# SMS_SEC_MGR_0_SMS_TIFS_SECMGR_44234000h register map
Vendor: Texas Instruments
Peripheral module from a debugger description file (folder AM275x).
Registers are 32-bit, read-write, reset 0x0 unless marked. A register's access mark holds for its fields unless they carry their own. Offsets are as the file gives them; lines under a group give offsets from that group; [hi:lo] are bit positions; {n}, {i} and the like mark numbered series; 'fields as' and 'values as' point back to an identical list; <NAME> marks a mode.

## SMS_TIFS_SECMGR
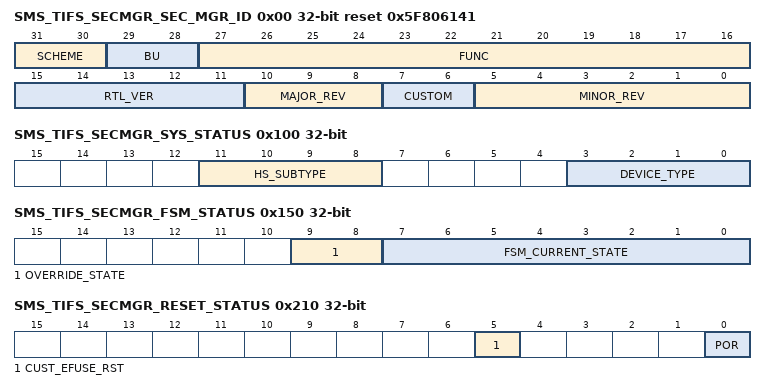
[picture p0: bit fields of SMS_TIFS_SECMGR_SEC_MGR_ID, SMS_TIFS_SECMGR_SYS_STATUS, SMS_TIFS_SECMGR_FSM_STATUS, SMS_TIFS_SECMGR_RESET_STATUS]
0x00 SMS_TIFS_SECMGR_SEC_MGR_ID ro reset 0x5F806141 — This is the standard TI peripheral ID register that exists at address 0 in the peripheral space
  [31:30] SCHEME — Used to distinguish which ID numbering scheme is used. Reset Source: sms_custom_rst_mod_g_rst_n
  [29:28] BU — BU identifier Reset Source: sms_custom_rst_mod_g_rst_n
  [27:16] FUNC — Module family. Reset Source: sms_custom_rst_mod_g_rst_n
  [15:11] RTL_VER — RTL version. R of X.Y.R.Z Reset Source: sms_custom_rst_mod_g_rst_n
  [10:8] MAJOR_REV — Major revision. X of X.Y.R.Z Reset Source: sms_custom_rst_mod_g_rst_n
  [7:6] CUSTOM — Special version number Reset Source: sms_custom_rst_mod_g_rst_n
  [5:0] MINOR_REV — Minor revision. Y of X.Y.R.Z Reset Source: sms_custom_rst_mod_g_rst_n
0x100 SMS_TIFS_SECMGR_SYS_STATUS ro — The System Status Register contains status information on the state of the security system. This is the only register that must be read to determine the status of the entire system. It is a readonly register and some bit will be replicated in other registers. This register is reset on POR only.
  [11:8] HS_SUBTYPE — HS/EMU Sub-type. 0xA = Field Securable. Else = Security Enforced 10 Field SecurableElse Security Enforced
  [3:0] DEVICE_TYPE — Decoded device type 4'b00 GENERAL_PURPOSE114'b01 TEST014'b10 EMULATOR014'b10 HIGH_SECURITY10Other BAD
0x150 SMS_TIFS_SECMGR_FSM_STATUS ro — The FSM Status Register contains Secure FSM state machine information
  [9:8] OVERRIDE_STATE — This is the override status 2'b00 No override2'b01 Override without SMS2'b10 Reserved2'b11 Override with SMS
  [7:0] FSM_CURRENT_STATE — This is the state machine FSM current state variable Reset Source: sms_custom_rst_mod_g_rst_n
0x210 SMS_TIFS_SECMGR_RESET_STATUS ro — The Reset Status Register provides visibility of resets within the system. These bits are read-only and will be cleared when a 1 is written to a given bit location. They will record the fact that a given reset occurred.
  [5] CUST_EFUSE_RST — Captures reset events on port: sec_efc_fclrz Reset Source: sms_custom_rst_mod_g_rst_n
  [0] POR — Captures reset events on port: por_rst_n Reset Source: sms_custom_rst_mod_g_rst_n
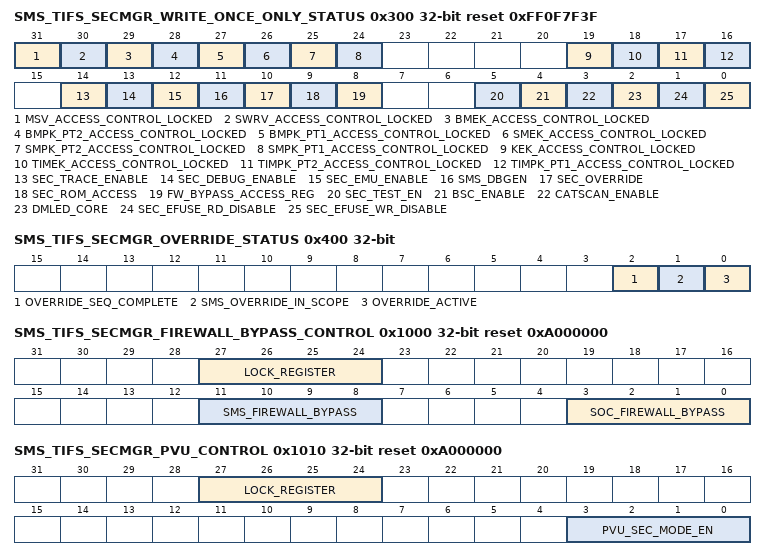
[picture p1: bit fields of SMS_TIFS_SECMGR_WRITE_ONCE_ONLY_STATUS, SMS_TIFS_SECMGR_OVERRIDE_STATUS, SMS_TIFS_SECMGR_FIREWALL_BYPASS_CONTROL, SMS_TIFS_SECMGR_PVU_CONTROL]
0x300 SMS_TIFS_SECMGR_WRITE_ONCE_ONLY_STATUS ro reset 0xFF0F7F3F — As a debug aid we need to be able to read the write-once only bits to know their state. This register makes all these write-once only flags visible in current state.
  [31] MSV_ACCESS_CONTROL_LOCKED — 0 MSV access control register locked1 MSV access control register not locked
  [30] SWRV_ACCESS_CONTROL_LOCKED — 0 SWRV access control register locked1 SWRV access control register not locked
  [29] BMEK_ACCESS_CONTROL_LOCKED — 0 BMEK access control register locked1 BMEK access control register not locked
  [28] BMPK_PT2_ACCESS_CONTROL_LOCKED — 0 BMPK-Part2 access control register locked1 BMPK-Part2 access control register not locked
  [27] BMPK_PT1_ACCESS_CONTROL_LOCKED — 0 BMPK-Part1 access control register locked1 BMPK-Part1 access control register not locked
  [26] SMEK_ACCESS_CONTROL_LOCKED — 0 SMEK access control register locked1 SMEK access control register not locked
  [25] SMPK_PT2_ACCESS_CONTROL_LOCKED — 0 SMPK-Part2 access control register locked1 SMPK-Part2 access control register not locked
  [24] SMPK_PT1_ACCESS_CONTROL_LOCKED — 0 SMPK-Part1 access control register locked1 SMPK-Part1 access control register not locked
  [19] KEK_ACCESS_CONTROL_LOCKED — 0 KEK access control register locked1 KEK access control register not locked
  [18] TIMEK_ACCESS_CONTROL_LOCKED — 0 TI MEK access control register locked1 TI MEK access control register not locked
  [17] TIMPK_PT2_ACCESS_CONTROL_LOCKED — 0 TI MPK-Part2 access control register locked1 TI MPK-Part2 access control register not locked
  [16] TIMPK_PT1_ACCESS_CONTROL_LOCKED — 0 TI MPK-Part1 access control register locked1 TI MPK-Part1 access control register not locked
  [14] SEC_TRACE_ENABLE — 0 Secure Trace Enable access control register locked1 Secure Trace Enable access control register not locked
  [13] SEC_DEBUG_ENABLE — 0 Secure Debug Enable access control register locked1 Secure Debug Enable access control register not locked
  [12] SEC_EMU_ENABLE — 0 Secure Emulation Enable access control register locked1 Secure Emulation Enable access control register not locked
  [11] SMS_DBGEN — 0 SMS Debug Enable access control register locked1 SMS Debug Enable access control register not locked
  [10] SEC_OVERRIDE — 0 Security Override access control register locked1 Security Override access control register not locked
  [9] SEC_ROM_ACCESS — 0 Secure ROM access control register locked1 Secure ROM access control register not locked
  [8] FW_BYPASS_ACCESS_REG — 0 Firewall Bypass access control register locked1 Firewall Bypass access control register not locked
  [5] SEC_TEST_EN — 0 Secure Test Enable access control register locked1 Secure Test Enable access control register not locked
  [4] BSC_ENABLE — 0 Boundary Scan Enable access control register locked1 Boundary Scan Enable access control register not locked
  [3] CATSCAN_ENABLE — 0 Catscan Enable access control register locked1 Catscan Enable access control register not locked
  [2] DMLED_CORE — 0 DMLED Core control register locked1 DMLED Core control register not locked
  [1] SEC_EFUSE_RD_DISABLE — 0 Security EFUSE Read Disable register locked1 Security EFUSE Read Disable register not locked
  [0] SEC_EFUSE_WR_DISABLE — 0 Security EFUSE Write Disable register locked1 Security EFUSE Write Disable register not locked
0x400 SMS_TIFS_SECMGR_OVERRIDE_STATUS ro — This Register reflects the status of Override request.
  [2] OVERRIDE_SEQ_COMPLETE — 1 HW Override sequence finished
  [1] SMS_OVERRIDE_IN_SCOPE — 0 SMS Override not active1 SMS Override active
  [0] OVERRIDE_ACTIVE — 0 Override not active0 Override active
0x700 SMS_TIFS_SECMGR_TI_MPK_PART1_STATUS_REG_j ro — This register echoes the TI MPK-Part1 value, the MPK value can be muted via MPK Access control register.
  [31:0] TI_MPK — TI MP value as read from TI MPK Data Reg. This register is mere echo of Data Register Reset Source: sms_custom_rst_mod_g_rst_n
0x750 SMS_TIFS_SECMGR_TI_MPK_PART2_STATUS_REG_j ro — This register echoes the TI MPK-Part2 value, the MPK value can be muted via MPK Access control register.
  fields as SMS_TIFS_SECMGR_TI_MPK_PART1_STATUS_REG_j
0x780 SMS_TIFS_SECMGR_TI_MEK_ID_STATUS_REG ro — This register echoes the TI MEK ID value, this is used to ID the key used for MEK.
  [31:0] TI_MEK_ID — TI MEK ID value as read from TI MEK ID data register, this is mere echo of TI MEK ID Register. Reset Source: sms_custom_rst_mod_g_rst_n
0x800 SMS_TIFS_SECMGR_SMPK_PART1_STATUS_REG_j ro — This register echoes the SMPK-Part1 value, the MPK value can be muted via MPK Access control register.
  [31:0] SMPK — SMPK value as read from SMPK Data Register. This register is mere echo of SMPK Data register. Reset Source: sms_custom_rst_mod_g_rst_n
0x850 SMS_TIFS_SECMGR_SMPK_PART2_STATUS_REG_j ro — This register echoes the SMPK-Part2 value, the MPK value can be muted via MPK Access control register.
  fields as SMS_TIFS_SECMGR_SMPK_PART1_STATUS_REG_j
0x880 SMS_TIFS_SECMGR_SMEK_ID_STATUS_REG ro — This register echoes the SMEK ID value, this is used to ID the key used for SMEK.
  [31:0] SMEK — SMEK ID value as read from SMEK ID data register, this is mere echo of SMEK ID Register. Reset Source: sms_custom_rst_mod_g_rst_n
0x900 SMS_TIFS_SECMGR_BMPK_PART1_STATUS_REG_j ro — This register echoes the BMPK-Part1 value, the MPK value can be muted via MPK Access control register.
  [31:0] BMPK — BMPK value as read from BMPK Data Register. This register is mere echo of BMPK Data register. Reset Source: sms_custom_rst_mod_g_rst_n
0x950 SMS_TIFS_SECMGR_BMPK_PART2_STATUS_REG_j ro — This register echoes the BMPK-Part2 value, the MPK value can be muted via MPK Access control register.
  fields as SMS_TIFS_SECMGR_BMPK_PART1_STATUS_REG_j
0x980 SMS_TIFS_SECMGR_BMEK_ID_STATUS_REG ro — This register echoes the BMEK ID value, this is used to ID the key used for BMEK.
  [31:0] BMEK — BMEK ID value as read from BMEK ID data register, this is mere echo of BMEK ID Register. Reset Source: sms_custom_rst_mod_g_rst_n
0xD00 SMS_TIFS_SECMGR_SWRV_STATUS_REG_j ro — This register echoes the SWRV value, the SWRV value can be muted via SWRV Access control register.
  [31:0] SWRV — SWRV value as read from SWRV Data Register. This register is mere echo of SWRV Data register. Reset Source: sms_custom_rst_mod_g_rst_n
0xD50 SMS_TIFS_SECMGR_MSV_STATUS_REG ro — This register echoes the MSV value, the MSV value can be muted via MSV Access control register.
  [23:0] MSV — MSV value as read from MSV Data Register. This register is mere echo of MSV Data register. Reset Source: sms_custom_rst_mod_g_rst_n
0x1000 SMS_TIFS_SECMGR_FIREWALL_BYPASS_CONTROL reset 0xA000000 — This register controls the bypass feature for all SoC firewall. Once locked, the register cannot be changed till POR.
  [27:24] LOCK_REGISTER — Unlock code is 0xA, if value is anything else the register locks, once locked this register cannot be changed till POR. Rest Register is locked10 Register is unlocked
  [11:8] SMS_FIREWALL_BYPASS — Writing code 0xA will put SMS firewall in bypass mode. Please refer to firewall spec for bypass mode operation. 0 Not in bypass mode10 Bypass
  [3:0] SOC_FIREWALL_BYPASS — Writing code 0xA will put all SoC firewall in bypass mode, excluding SMS. Please refer to firewall spec for bypass mode operation 0 Not in bypass mode10 Bypass
0x1010 SMS_TIFS_SECMGR_PVU_CONTROL reset 0xA000000 — This register controls the security of PVU/IO-MMU module. Once locked, the register cannot be changed till POR.
  [27:24] LOCK_REGISTER — Unlock code is 0xA, if value is anything else the register locks, once locked this register cannot be changed till POR. Reset Source: sms_custom_rst_mod_g_rst_n
  [3:0] PVU_SEC_MODE_EN — Writing code 0xA allows PVC to operate in secure mode. Reset Source: sms_custom_rst_mod_g_rst_n
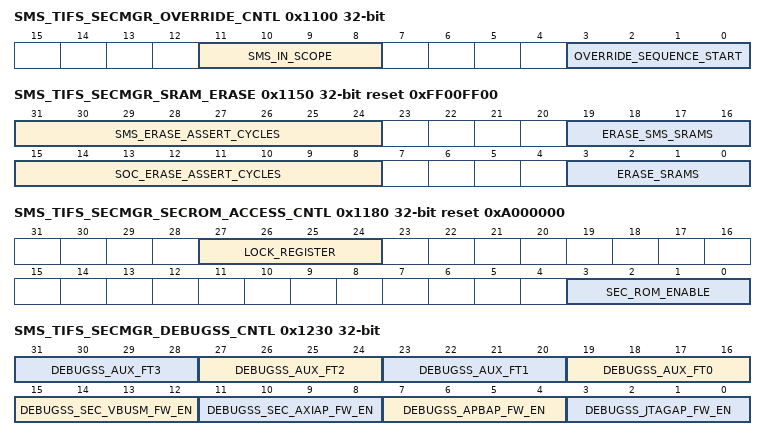
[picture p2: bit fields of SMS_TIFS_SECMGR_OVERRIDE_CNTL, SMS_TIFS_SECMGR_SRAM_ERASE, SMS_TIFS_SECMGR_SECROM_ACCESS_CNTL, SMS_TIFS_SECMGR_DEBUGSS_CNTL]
0x1100 SMS_TIFS_SECMGR_OVERRIDE_CNTL — Override sequence start register, writing 0xA start the override sequence as documented. This register can only be written once during each POR and the value is sticky.
  [11:8] SMS_IN_SCOPE — Writing code 0xA will put SMS also in in scope of override, please refer to flow in previous section. This must be set along with override_sequence_start. Reset Source: sms_custom_rst_mod_g_rst_n
  [3:0] OVERRIDE_SEQUENCE_START — Override sequence start bit, Writing 0xA starts the operation Reset Source: sms_custom_rst_mod_g_rst_n
0x1104 SMS_TIFS_SECMGR_OVERRIDE_DELAY_LOOP reset 0xFFFF — This register holds delay loop counter to allow SMS to enter WFI before SMS override is effeictive.
  [31:0] SMS_OVERRIDE_DELAY_LOOP_CNT — SMS Delay loop counter, override is effective when counter reaches Zero. This counter is running on PLL output clock , hence ROM/SW must ensure delay based on system PLL SMS clock. Reset Source: sms_custom_rst_mod_g_rst_n
0x1150 SMS_TIFS_SECMGR_SRAM_ERASE reset 0xFF00FF00 — This register control the Erase function of SRAM and ROM access control.
  [31:24] SMS_ERASE_ASSERT_CYCLES — This MMR control the assertion time of SMS Erase signal. This is required as certain SRAM erase logic may have time requirement to keep signal asserted. Runs as same clock as Sec-mgr clock. Reset Source: sms_custom_rst_mod_g_rst_n
  [19:16] ERASE_SMS_SRAMS — Writing code 0xA will send signal to erase SMS SRAM, this will erase all SMS SRAM including data and code SRAM. Care must be taken to ensure SMS Cortex-M4F is in not executing from SRAM when this signal is asserted. Reset Source: sms_custom_rst_mod_g_rst_n
  [15:8] SOC_ERASE_ASSERT_CYCLES — This MMR control the assertion time of SOC Erase signal. This is required as certain SRAM erase logic may have time requirement to keep signal asserted. Runs as same clock as Sec-mgr clock. Reset Source: sms_custom_rst_mod_g_rst_n
  [3:0] ERASE_SRAMS — Writing code 0xA will send signal to all SoC level SRAM to erase the RAM. This bit does not erase SMS internal SRAM. Reset Source: sms_custom_rst_mod_g_rst_n
0x1180 SMS_TIFS_SECMGR_SECROM_ACCESS_CNTL reset 0xA000000 — This register controls the Erase function of SRAM and ROM access control.
  [27:24] LOCK_REGISTER — Unlock code is 0xA, if value is anything else the register locks, once locked this register cannot be changed till POR Reset Source: sms_custom_rst_mod_g_rst_n
  [3:0] SEC_ROM_ENABLE — Writing code 0xA will enable access to secure ROM, for all other value the secure ROM is disabled. Reset Source: sms_custom_rst_mod_g_rst_n
0x1220 SMS_TIFS_SECMGR_DEBUGSS_DOM reset 0x3CE — This register controls the DebugSS DOM
  [10:0] DEBUGSS_SEC_CTL_DOM — DOM value as per DebugSS spec Reset Source: sms_custom_rst_mod_g_rst_n
0x1230 SMS_TIFS_SECMGR_DEBUGSS_CNTL — This register controls DebugSS Internal Firewall. This register can be locked. Once locked, the register cannot be changed until POR
  [4n+19:4n+16] DEBUGSS_AUX_FT{n} (n=0..3) — Writing code 0xA will assert signal debugss_aux_ft_signals bit {n} Reset Source: sms_custom_rst_mod_g_rst_n
  [15:12] DEBUGSS_SEC_VBUSM_FW_EN — Writing code 0xA will enable DebugSS internal VBUSM firewall interface, else it is disabled Reset Source: sms_custom_rst_mod_g_rst_n
  [11:8] DEBUGSS_SEC_AXIAP_FW_EN — Writing code 0xA will enable DebugSS internal AXI AP firewall interface, else it is disabled Reset Source: sms_custom_rst_mod_g_rst_n
  [7:4] DEBUGSS_APBAP_FW_EN — Writing code 0xA will enable DebugSS internal APB AP firewall interface, else it is disabled Reset Source: sms_custom_rst_mod_g_rst_n
  [3:0] DEBUGSS_JTAGAP_FW_EN — Writing code 0xA will enable DebugSS internal JTAG firewall interface, else it is disabled Reset Source: sms_custom_rst_mod_g_rst_n
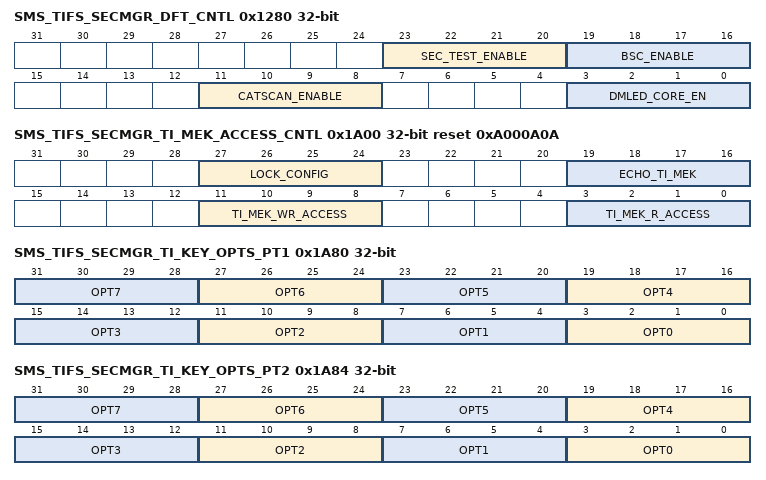
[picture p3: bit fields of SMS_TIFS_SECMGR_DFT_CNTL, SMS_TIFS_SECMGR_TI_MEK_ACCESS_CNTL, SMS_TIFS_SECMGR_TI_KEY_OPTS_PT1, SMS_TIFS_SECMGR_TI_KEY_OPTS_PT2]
0x1280 SMS_TIFS_SECMGR_DFT_CNTL — This register controls the DFT access of the device. These bits can only be written once during each POR.
  [23:20] SEC_TEST_ENABLE — Control the use of Test Enable. Writing a 0xA will enable test Reset Source: sms_custom_rst_mod_g_rst_n
  [19:16] BSC_ENABLE — Control the use of Boundary Scan Chain. Writing a 0xA will enable BSCAN Reset Source: sms_custom_rst_mod_g_rst_n
  [11:8] CATSCAN_ENABLE — Control the use of the CatScan module. Writing a 0xA will enable CATSCAN Reset Source: sms_custom_rst_mod_g_rst_n
  [3:0] DMLED_CORE_EN — Writing code 0xA will allow DMLED module to operate. Else DMLED mode is disabled. Reset Source: sms_custom_rst_mod_g_rst_n
0x1810 SMS_TIFS_SECMGR_TI_MPK_PT1_DATA_REG_j — This register hold the TI MPK-Part1 value, the TI MPK-Part1 access/permission is controlled TI MPK-Part1 Access control register.
  [31:0] TI_MPK — TI MPK-Part1 value as read from Efuses. Reset Source: sms_custom_rst_mod_g_rst_n
0x1910 SMS_TIFS_SECMGR_TI_MPK_PT2_DATA_REG_j — This register hold the TI MPK-Part2 value, the TI MPK-Part2 access/permission is controlled TI MPK-Part2 Access control register.
  [31:0] TI_MPK — TI MPK-Part2 value as read from Efuses. Reset Source: sms_custom_rst_mod_g_rst_n
0x1A00 SMS_TIFS_SECMGR_TI_MEK_ACCESS_CNTL reset 0xA000A0A — This Register controls the access/permission of all TI MEK Data Registers. If both Read and Write access are not selected, than all TI MEK Data registers become invisible.
  [27:24] LOCK_CONFIG — Unlock code is 0xA. If value is anything else the register locks, once locked this register cannot be changed til POR Reset Source: sms_custom_rst_mod_g_rst_n
  [19:16] ECHO_TI_MEK — Writing code 0xA will echo TI MEK ID value in status register, this can used by public code to check the key used for Encryption. This must NOT be function of actual TI MEK value, rather a mere index. Reset Source: sms_custom_rst_mod_g_rst_n
  [11:8] TI_MEK_WR_ACCESS — 0xA Write Access allowed. Else: No write access Reset Source: sms_custom_rst_mod_g_rst_n
  [3:0] TI_MEK_R_ACCESS — 0xA Read Access allowed. Else: No Read access. Reset Source: sms_custom_rst_mod_g_rst_n
0x1A04 SMS_TIFS_SECMGR_TI_MEK_ID — TI MEK ID Data Register
  [31:0] TI_MEK_ID — TI MEK ID, used by public code to check the key used for Encryption. This must NOT be function of actual TI MEK value, rather a mere index. SW has full flexibility to use these 32-bits as desired to ID the TI MEK key. Reset Source: sms_custom_rst_mod_g_rst_n
0x1A10 SMS_TIFS_SECMGR_TI_MEK_DATA_REG_j — This register hold the TI MEK value, the TI MEK access/permission is controlled MEK Access control register.
  [31:0] TI_MEK — TI MEK value as read from Efuses. Reset Source: sms_custom_rst_mod_g_rst_n
0x1A80 SMS_TIFS_SECMGR_TI_KEY_OPTS_PT1 — This field is TI defined Keys options
  [4n+3:4n] OPT{n} (n=0..7) — If the value is 0xA, option is active. Else option is de-activated Reset Source: sms_custom_rst_mod_g_rst_n
0x1A84 SMS_TIFS_SECMGR_TI_KEY_OPTS_PT2 — This field is TI defined Keys options
  fields as SMS_TIFS_SECMGR_TI_KEY_OPTS_PT1
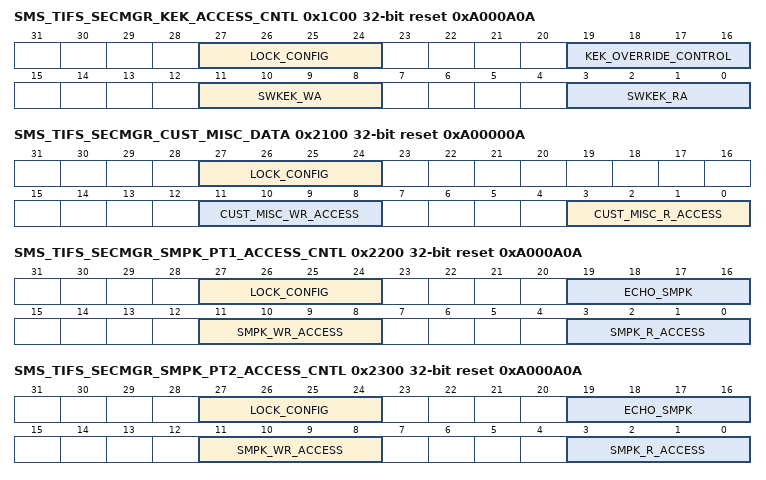
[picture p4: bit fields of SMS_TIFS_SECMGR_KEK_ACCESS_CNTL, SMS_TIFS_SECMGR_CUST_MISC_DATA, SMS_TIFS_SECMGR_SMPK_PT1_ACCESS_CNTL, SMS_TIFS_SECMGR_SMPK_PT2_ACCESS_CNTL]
0x1C00 SMS_TIFS_SECMGR_KEK_ACCESS_CNTL reset 0xA000A0A — This Register controls the access/permission of all KEK Data Registers. If both Read and Write access are not selected, than all KEK Data registers become invisible.
  [27:24] LOCK_CONFIG — Unlock code is 0xA, if value is anything else the register locks, once locked this register cannot be changed til POR Reset Source: sms_custom_rst_mod_g_rst_n
  [19:16] KEK_OVERRIDE_CONTROL — 0xA Override KEK output to value from KEK override registers. Else KEK is as coming from KEK Efuses Reset Source: sms_custom_rst_mod_g_rst_n
  [11:8] SWKEK_WA — 0xA Write Access allowed to SW KEK register. Else No write access Reset Source: sms_custom_rst_mod_g_rst_n
  [3:0] SWKEK_RA — 0xA Write Access allowed to SW KEK register. Else No write access Reset Source: sms_custom_rst_mod_g_rst_n
0x2100 SMS_TIFS_SECMGR_CUST_MISC_DATA reset 0xA00000A — This Register controls the access/permission of all Customer Misc Data Registers. If both Read and Write access are not selected, than all CUST MISC Data registers become invisible.
  [27:24] LOCK_CONFIG — Unlock code is 0xA, if value is anything else the register locks, once locked this register cannot be changed till POR. Reset Source: sms_custom_rst_mod_g_rst_n
  [11:8] CUST_MISC_WR_ACCESS — 0xA Write Access allowed. Else: No write access Reset Source: sms_custom_rst_mod_g_rst_n
  [3:0] CUST_MISC_R_ACCESS — 0xA Read Access allowed. Else: No Read access. Reset Source: sms_custom_rst_mod_g_rst_n
0x2110 SMS_TIFS_SECMGR_CUST_MISC_DATA_REG_j — This register hold the CUST MISC value, the CUST MISC access/permission is controlled CUST MISC Access control register. This can be used by customer to store critical security flags/data.
  [31:0] CUST_MISC — CUST MISC value. ROM/HW does no action based on value of this register. Reset Source: sms_custom_rst_mod_g_rst_n
0x2200 SMS_TIFS_SECMGR_SMPK_PT1_ACCESS_CNTL reset 0xA000A0A — This Register controls the access/permission of all SMPK-Part1 Data Registers. If both Read and Write access are not selected, than all SMPK Data registers become invisible.
  [27:24] LOCK_CONFIG — Unlock code is 0xA, if value is anything else the register locks, once locked this register cannot be changed till POR. Reset Source: sms_custom_rst_mod_g_rst_n
  [19:16] ECHO_SMPK — Writing code 0xA will echo SMPK value in SMPK read only Status registers. Reset Source: sms_custom_rst_mod_g_rst_n
  [11:8] SMPK_WR_ACCESS — 0xA Write Access allowed. Else: No write access Reset Source: sms_custom_rst_mod_g_rst_n
  [3:0] SMPK_R_ACCESS — 0xA Read Access allowed. Else: No Read access. Reset Source: sms_custom_rst_mod_g_rst_n
0x2210 SMS_TIFS_SECMGR_SMPK_PT1_DATA_REG_j — This register hold the SMPK-Part1 value, the SMPK-Part1 access/permission is controlled SMPK-Part1 Access control register.
  [31:0] SMPK — SMPK-Part1 value as read from Efuses Reset Source: sms_custom_rst_mod_g_rst_n
0x2300 SMS_TIFS_SECMGR_SMPK_PT2_ACCESS_CNTL reset 0xA000A0A — This Register controls the access/permission of all SMPK-Part2 Data Registers. If both Read and Write access are not selected, than all SMPK-Part2 Data registers become invisible in both control and status sections.
  fields as SMS_TIFS_SECMGR_SMPK_PT1_ACCESS_CNTL
0x2310 SMS_TIFS_SECMGR_SMPK_PT2_DATA_REG_j — This register hold the SMPK-Part2 value, the SMPK-Part2 access/permission is controlled SMPK-Part2 Access control register.
  [31:0] SMPK — SMPK-Part2 value as read from Efuses Reset Source: sms_custom_rst_mod_g_rst_n
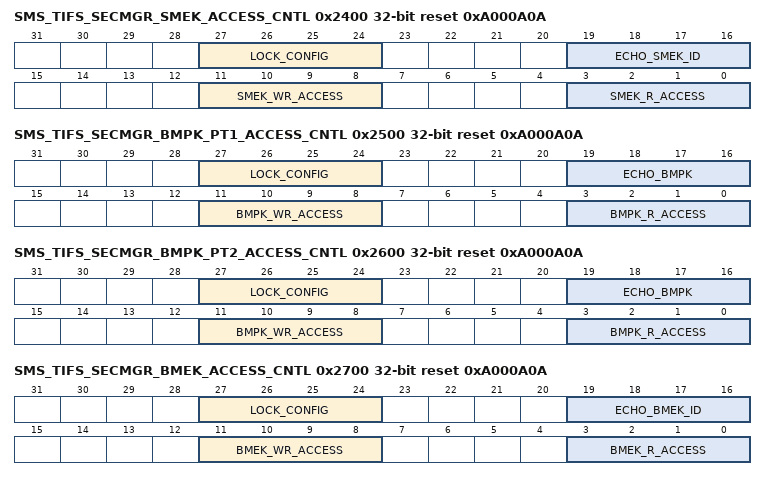
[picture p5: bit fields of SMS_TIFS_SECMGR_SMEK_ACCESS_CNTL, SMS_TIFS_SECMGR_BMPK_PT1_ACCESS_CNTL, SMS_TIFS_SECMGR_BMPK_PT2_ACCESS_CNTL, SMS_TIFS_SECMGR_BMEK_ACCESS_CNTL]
0x2400 SMS_TIFS_SECMGR_SMEK_ACCESS_CNTL reset 0xA000A0A — This Register controls the access/permission of all SMEK Data Registers. If both Read and Write access are not selected, than all SMEK Data registers become invisible.
  [27:24] LOCK_CONFIG — Writing code 0xA lock the config, once locked TI MPK access as set in this register cannot be changed till POR. Reset Source: sms_custom_rst_mod_g_rst_n
  [19:16] ECHO_SMEK_ID — Writing code 0xA will echo SMEK ID value in status register, this can used by public code to check the key used for Encryption. This must NOT be function of actual SMEK value, rather a mere index. Reset Source: sms_custom_rst_mod_g_rst_n
  [11:8] SMEK_WR_ACCESS — 0xA Write Access allowed. Else: No write access Reset Source: sms_custom_rst_mod_g_rst_n
  [3:0] SMEK_R_ACCESS — 0xA Read Access allowed. Else: No Read access. Reset Source: sms_custom_rst_mod_g_rst_n
0x2404 SMS_TIFS_SECMGR_SMEK_ID — SMEK ID Data Register
  [31:0] SMEK_ID — SMEK ID, used by public code to check the key used for Encryption. This must NOT be function of actual SMEK value, rather a mere index. SW has full flexibility to use these 32-bits as desired to ID the SMEK key. Reset Source: sms_custom_rst_mod_g_rst_n
0x2410 SMS_TIFS_SECMGR_SMEK_DATA_REG_j — This register hold the SMEK value, the SMEK access/permission is controlled MEK Access control register.
  [31:0] SMEK — SMEK value as read from Efuses Reset Source: sms_custom_rst_mod_g_rst_n
0x2500 SMS_TIFS_SECMGR_BMPK_PT1_ACCESS_CNTL reset 0xA000A0A — This Register controls the access/permission of all BMPK-Part1 Data Registers. If both Read and Write access are not selected, than all BMPK-Part1 Data registers become invisible in both status and control sections.
  [27:24] LOCK_CONFIG — Unlock code is 0xA, if value is anything else the register locks, once locked this register cannot be changed till POR. Reset Source: sms_custom_rst_mod_g_rst_n
  [19:16] ECHO_BMPK — Writing code 0xA will echo BMPK value in BMPK read only Status registers Reset Source: sms_custom_rst_mod_g_rst_n
  [11:8] BMPK_WR_ACCESS — 0xA Write Access allowed. Else: No write access. Reset Source: sms_custom_rst_mod_g_rst_n
  [3:0] BMPK_R_ACCESS — 0xA Read Access allowed. Else: No Read access. Reset Source: sms_custom_rst_mod_g_rst_n
0x2510 SMS_TIFS_SECMGR_BMPK_PT1_DATA_REG_j — This register hold the BMPK-Part1 value, the BMPK-Part1 access/permission is controlled BMPK-Part1 Access control register.
  [31:0] BMPK — BMPK-Part1 value as read from Efuses Reset Source: sms_custom_rst_mod_g_rst_n
0x2600 SMS_TIFS_SECMGR_BMPK_PT2_ACCESS_CNTL reset 0xA000A0A — This Register controls the access/permission of all BMPK-Part2 Data Registers. If both Read and Write access are not selected, than all BMPK-Part2 Data registers become invisible in both status and control sections.
  fields as SMS_TIFS_SECMGR_BMPK_PT1_ACCESS_CNTL
0x2610 SMS_TIFS_SECMGR_BMPK_PT2_DATA_REG_j — This register hold the BMPK-Part2 value, the BMPK-Part2 access/permission is controlled BMPK-Part2 Access control register.
  [31:0] BMPK — BMPK-Part2 value as read from Efuses Reset Source: sms_custom_rst_mod_g_rst_n
0x2700 SMS_TIFS_SECMGR_BMEK_ACCESS_CNTL reset 0xA000A0A — This Register controls the access/permission of all BMEK Data Registers. If both Read and Write access are not selected, than all BMEK Data registers become invisible.
  [27:24] LOCK_CONFIG — Unlock code is 0xA, if value is anything else the register locks, once locked this register cannot be changed till POR. Reset Source: sms_custom_rst_mod_g_rst_n
  [19:16] ECHO_BMEK_ID — Writing code 0xA will echo BMEK ID value in status register, this can used by public code to check the key used for Encryption. This must NOT be function of actual BMEK value, rather a mere index. Reset Source: sms_custom_rst_mod_g_rst_n
  [11:8] BMEK_WR_ACCESS — 0xA Write Access allowed. Else: No write access Reset Source: sms_custom_rst_mod_g_rst_n
  [3:0] BMEK_R_ACCESS — 0xA Read Access allowed. Else: No Read access. Reset Source: sms_custom_rst_mod_g_rst_n
0x2704 SMS_TIFS_SECMGR_BMEK_ID — BMEK ID Data Register
  [31:0] BMEK_ID — BMEK ID, used by public code to check the key used for Encryption. This must NOT be function of actual BMEK value, rather a mere index. SW has full flexibility to use these 32-bits as desired to ID the BMEK key. Reset Source: sms_custom_rst_mod_g_rst_n
0x2710 SMS_TIFS_SECMGR_BMEK_DATA_REG_j — This register hold the BMEK value, the BMEK access/permission is controlled MEK Access control register.
  [31:0] BMEK — BMEK value as read from Efuses Reset Source: sms_custom_rst_mod_g_rst_n
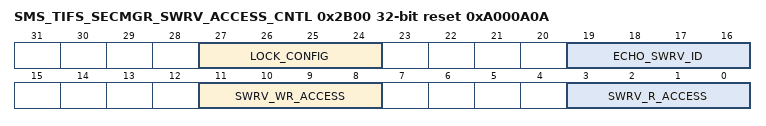
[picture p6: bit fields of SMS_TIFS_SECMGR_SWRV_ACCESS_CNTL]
0x2B00 SMS_TIFS_SECMGR_SWRV_ACCESS_CNTL reset 0xA000A0A — This Register controls the access/permission of all SWRV Data Registers. If both Read and Write access are not selected, than all SWRV Data registers become invisible.
  [27:24] LOCK_CONFIG — Unlock code is 0xA, if value is anything else the register locks, once locked this register cannot be changed till POR Reset Source: sms_custom_rst_mod_g_rst_n
  [19:16] ECHO_SWRV_ID — Writing code 0xA will echo SWRV ID value in status register, this can used by public code to check the key used for Encryption. This must NOT be function of actual SWRV value, rather a mere index. Reset Source: sms_custom_rst_mod_g_rst_n
  [11:8] SWRV_WR_ACCESS — 0xA Write Access allowed. Else: No write access Reset Source: sms_custom_rst_mod_g_rst_n
  [3:0] SWRV_R_ACCESS — 0xA Read Access allowed. Else: No Read access. Reset Source: sms_custom_rst_mod_g_rst_n
0x2B10 SMS_TIFS_SECMGR_SWRV_DATA_REG_j — This register hold the SWRV value, the SWRV access/permission is controlled SWRV Access control register.
  [31:0] SWRV — SWRV value as read from efuse. ROM/SW does triple redundancy on these bits. Reset Source: sms_custom_rst_mod_g_rst_n
